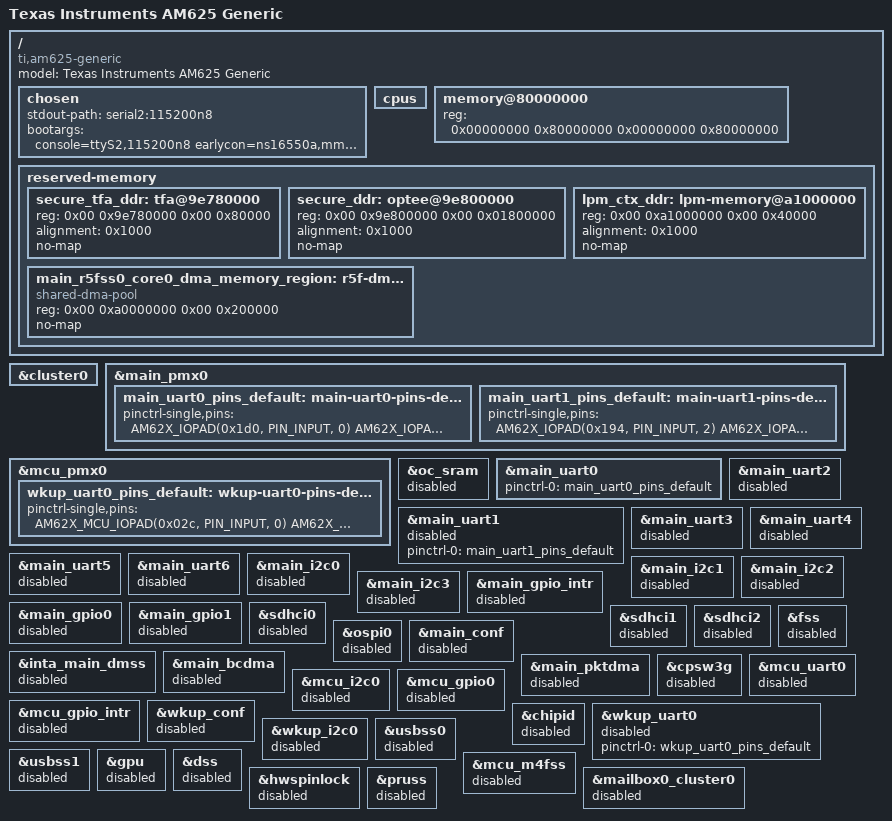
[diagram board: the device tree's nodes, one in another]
// SPDX-License-Identifier: GPL-2.0
/*
 * AM625 Minimal dts file
 * Copyright (C) 2021-2022 Texas Instruments Incorporated - https://www.ti.com/
 */

/dts-v1/;

#include <dt-bindings/leds/common.h>
#include <dt-bindings/gpio/gpio.h>
#include "k3-am625.dtsi"

/ {
	compatible =  "ti,am625-generic", "ti,am625";
	model = "Texas Instruments AM625 Generic";

	chosen {
		stdout-path = "serial2:115200n8";
		bootargs = "console=ttyS2,115200n8 earlycon=ns16550a,mmio32,0x02800000";
	};

	cpus {
		/delete-node/ cpu@1;
		/delete-node/ cpu@2;
		/delete-node/ cpu@3;
	};

	memory@80000000 {
		device_type = "memory";
		/* 2G RAM */
		reg = <0x00000000 0x80000000 0x00000000 0x80000000>;

	};

	reserved-memory {
		#address-cells = <2>;
		#size-cells = <2>;
		ranges;

		secure_tfa_ddr: tfa@9e780000 {
			reg = <0x00 0x9e780000 0x00 0x80000>;
			alignment = <0x1000>;
			no-map;
		};

		secure_ddr: optee@9e800000 {
			reg = <0x00 0x9e800000 0x00 0x01800000>; /* for OP-TEE */
			alignment = <0x1000>;
			no-map;
		};

		main_r5fss0_core0_dma_memory_region: r5f-dma-memory@a0000000 {
			compatible = "shared-dma-pool";
			reg = <0x00 0xa0000000 0x00 0x200000>;
			no-map;
		};

		lpm_ctx_ddr: lpm-memory@a1000000 {
			reg = <0x00 0xa1000000 0x00 0x40000>;
			alignment = <0x1000>;
			no-map;
		};
	};
};

&cluster0 {
	/delete-node/ core1;
	/delete-node/ core2;
	/delete-node/ core3;
};

&main_pmx0 {
	main_uart0_pins_default: main-uart0-pins-default {
		pinctrl-single,pins = <
			AM62X_IOPAD(0x1d0, PIN_INPUT, 0) /* (A15) UART0_CTSn */
			AM62X_IOPAD(0x1d4, PIN_OUTPUT, 0) /* (B15) UART0_RTSn */
			AM62X_IOPAD(0x1c8, PIN_INPUT, 0) /* (D14) UART0_RXD */
			AM62X_IOPAD(0x1cc, PIN_OUTPUT, 0) /* (E14) UART0_TXD */
		>;
	};

	main_uart1_pins_default: main-uart1-pins-default {
		pinctrl-single,pins = <
			AM62X_IOPAD(0x194, PIN_INPUT, 2) /* (B19) MCASP0_AXR3.UART1_CTSn */
			AM62X_IOPAD(0x198, PIN_OUTPUT, 2) /* (A19) MCASP0_AXR2.UART1_RTSn */
			AM62X_IOPAD(0x1ac, PIN_INPUT, 2) /* (E19) MCASP0_AFSR.UART1_RXD */
			AM62X_IOPAD(0x1b0, PIN_OUTPUT, 2) /* (A20) MCASP0_ACLKR.UART1_TXD */
		>;
	};
};

&mcu_pmx0 {
	wkup_uart0_pins_default: wkup-uart0-pins-default {
		pinctrl-single,pins = <
			AM62X_MCU_IOPAD(0x02c, PIN_INPUT, 0) /* (C6) WKUP_UART0_CTSn */
			AM62X_MCU_IOPAD(0x030, PIN_OUTPUT, 0) /* (A4) WKUP_UART0_RTSn */
			AM62X_MCU_IOPAD(0x024, PIN_INPUT, 0) /* (B4) WKUP_UART0_RXD */
			AM62X_MCU_IOPAD(0x028, PIN_OUTPUT, 0) /* (C5) WKUP_UART0_TXD */
		>;
	};
};


&oc_sram {
	status = "disabled";
};

&main_uart0 {
	pinctrl-names = "default";
	pinctrl-0 = <&main_uart0_pins_default>;
};

&main_uart1 {
        pinctrl-names = "default";
        pinctrl-0 = <&main_uart1_pins_default>;
        /* Main UART1 is used by TIFS firmware */
	status = "reserved";
};

&main_uart2 {
	status = "disabled";
};

&main_uart3 {
	status = "disabled";
};

&main_uart4 {
	status = "disabled";
};

&main_uart5 {
	status = "disabled";
};

&main_uart6 {
	status = "disabled";
};

&main_i2c0 {
	status = "disabled";

};

&main_i2c1 {
	status = "disabled";
};

&main_i2c2 {
	status = "disabled";
};

&main_i2c3 {
	status = "disabled";
};

&main_gpio_intr {
	status = "disabled";
};

&main_gpio0 {
	status = "disabled";
};

&main_gpio1 {
	status = "disabled";
};

&sdhci0 {
	status = "disabled";
};

&sdhci1 {
	status = "disabled";
};

&sdhci2 {
	status = "disabled";
};

&fss {
	status = "disabled";
};

&ospi0 {
	status = "disabled";
};

&main_conf {
	status = "disabled";
};

&inta_main_dmss {
	status = "disabled";
};

&main_bcdma {
	status = "disabled";
};

&main_pktdma {
	status = "disabled";
};

&cpsw3g {
	status = "disabled";
};

/* MCU periperhals */
&mcu_uart0 {
	status = "disabled";
};

&mcu_i2c0 {
	status = "disabled";
};

&mcu_gpio_intr {
	status = "disabled";
};

&mcu_gpio0 {
	status = "disabled";
};

/* WKUP periperhals */
&wkup_conf {
	status = "disabled";
};

&chipid {
	status = "disabled";
};

/* wkup_uart0 is reserved for firmware usage */
&wkup_uart0 {
	pinctrl-names = "default";
        pinctrl-0 = <&wkup_uart0_pins_default>;
        /* WKUP UART0 is used by DM firmware */
	status = "reserved";
};

&wkup_i2c0 {
	status = "disabled";
};

&usbss0 {
	status = "disabled";
};

&usbss1 {
	status = "disabled";
};

&gpu {
	status = "disabled";
};

&dss {
	status = "disabled";
};

&mcu_m4fss {
	status = "disabled";
};

&hwspinlock {
	status = "disabled";
};

&mailbox0_cluster0 {
	status = "disabled";
};

&pruss {
	status = "disabled";
};
